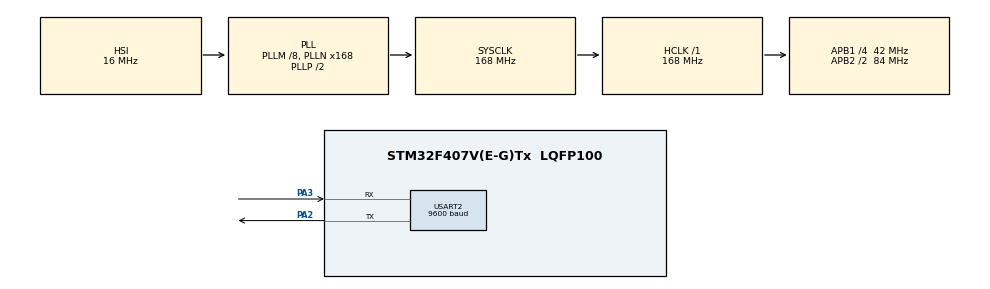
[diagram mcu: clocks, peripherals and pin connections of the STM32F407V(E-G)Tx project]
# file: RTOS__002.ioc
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FREERTOS.Tasks01=defaultTask,0,128,StartDefaultTask,Default,NULL,Dynamic,NULL,NULL
FREERTOS.configUSE_COUNTING_SEMAPHORES=1
Mcu.Family=STM32F4
Mcu.Name=STM32F407V(E-G)Tx
Mcu.Package=LQFP100
NVIC.PriorityGroup=NVIC_PRIORITYGROUP_4
NVIC.TIM1_UP_TIM10_IRQn=true\:15\:0\:false\:false\:true\:false\:false\:true\:true
NVIC.TimeBase=TIM1_UP_TIM10_IRQn
NVIC.TimeBaseIP=TIM1
NVIC.USART2_IRQn=true\:5\:0\:false\:false\:true\:true\:true\:true\:true
PA2.Mode=Asynchronous
PA2.Signal=USART2_TX
PA3.Mode=Asynchronous
PA3.Signal=USART2_RX
PH0-OSC_IN.Mode=HSE-External-Oscillator
PH0-OSC_IN.Signal=RCC_OSC_IN
PH1-OSC_OUT.Mode=HSE-External-Oscillator
PH1-OSC_OUT.Signal=RCC_OSC_OUT
ProjectManager.HeapSize=0x200
ProjectManager.StackSize=0x400
ProjectManager.TargetToolchain=STM32CubeIDE
RCC.48MHZClocksFreq_Value=84000000
RCC.AHBFreq_Value=168000000
RCC.APB1CLKDivider=RCC_HCLK_DIV4
RCC.APB1Freq_Value=42000000
RCC.APB1TimFreq_Value=84000000
RCC.APB2CLKDivider=RCC_HCLK_DIV2
RCC.APB2Freq_Value=84000000
RCC.APB2TimFreq_Value=168000000
RCC.CortexFreq_Value=168000000
RCC.HCLKFreq_Value=168000000
RCC.HSE_VALUE=8000000
RCC.HSI_VALUE=16000000
RCC.LSE_VALUE=32768
RCC.PLLM=8
RCC.PLLN=168
RCC.SYSCLKFreq_VALUE=168000000
RCC.SYSCLKSource=RCC_SYSCLKSOURCE_PLLCLK
RCC.VCOOutputFreq_Value=336000000
USART2.BaudRate=9600
USART2.VirtualMode=VM_ASYNC
VP_FREERTOS_VS_CMSIS_V1.Mode=CMSIS_V1
VP_SYS_VS_tim1.Mode=TIM1
board=custom

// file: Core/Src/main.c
/* USER CODE BEGIN Header */
/**
  ******************************************************************************
  * @file           : main.c
  * @brief          : Main program body
  ******************************************************************************
  * @attention
  *
  * Copyright (c) 2023 STMicroelectronics.
  * All rights reserved.
  *
  * This software is licensed under terms that can be found in the LICENSE file
  * in the root directory of this software component.
  * If no LICENSE file comes with this software, it is provided AS-IS.
  *
  ******************************************************************************
  */
/* USER CODE END Header */
#include "main.h"
// #include "cmsis_os.h"

/* USER CODE BEGIN Includes */

#include "FreeRTOS.h"
#include "task.h"
#include "timers.h"
#include "queue.h"
#include "semphr.h"
#include "event_groups.h"

#include "string.h"
#include "stdlib.h"

/* USER CODE END Includes */

UART_HandleTypeDef huart2;

osThreadId defaultTaskHandle;

void SystemClock_Config(void);
static void MX_GPIO_Init(void);
static void MX_USART2_UART_Init(void);

/* USER CODE BEGIN 0 */

// Create Task Defines

TaskHandle_t HPThandler;
void HPT_TASK(void *pvParameters);

TaskHandle_t MPThandler;
void MPT_TASK(void *pvParameters);

TaskHandle_t LPThandler;
void LPT_TASK(void *pvParameters);

TaskHandle_t VLPThandler;
void VLPT_TASK(void *pvParameters);

SemaphoreHandle_t CountingSem;

int resource[3] = {111,222,333};
int idx = 0;

uint8_t rx_data = 0;

/* USER CODE END 0 */

int main(void)
{

  /* MCU Configuration--------------------------------------------------------*/

  /* Reset of all peripherals, Initializes the Flash interface and the Systick. */
  HAL_Init();

  /* Configure the system clock */
  SystemClock_Config();

  /* Initialize all configured peripherals */
  MX_GPIO_Init();
  MX_USART2_UART_Init();
  /* USER CODE BEGIN 2 */

  CountingSem = xSemaphoreCreateCounting(3,0);

  if(CountingSem == NULL)
  {
	  HAL_UART_Transmit(&huart2, (uint8_t *)"Unable to Create Semaphore\n\n",28, 100);
  }
  else
  {
	  HAL_UART_Transmit(&huart2, (uint8_t *)"Counting Semaphorec created successfully\n\n",41, 100);
  }

  xTaskCreate(HPT_TASK, "HPT",128, NULL, 3, &HPThandler);
  xTaskCreate(MPT_TASK, "MPT",128, NULL, 2, &MPThandler);
  xTaskCreate(LPT_TASK, "LPT",128, NULL, 1, &LPThandler);
  xTaskCreate(VLPT_TASK, "VLPT",128, NULL, 0, &VLPThandler);

  vTaskStartScheduler();

  /* USER CODE END 2 */

  /* Create the thread(s) */
  /* definition and creation of defaultTask */

  /* We should never get here as control is now taken by the scheduler */
  /* Infinite loop */
  while (1)
  {

  }
}

void SystemClock_Config(void)
{
  RCC_OscInitTypeDef RCC_OscInitStruct = {0};
  RCC_ClkInitTypeDef RCC_ClkInitStruct = {0};

  /** Configure the main internal regulator output voltage
  */
  __HAL_RCC_PWR_CLK_ENABLE();
  __HAL_PWR_VOLTAGESCALING_CONFIG(PWR_REGULATOR_VOLTAGE_SCALE1);

  /** Initializes the RCC Oscillators according to the specified parameters
  * in the RCC_OscInitTypeDef structure.
  */
  RCC_OscInitStruct.OscillatorType = RCC_OSCILLATORTYPE_HSI;
  RCC_OscInitStruct.HSIState = RCC_HSI_ON;
  RCC_OscInitStruct.HSICalibrationValue = RCC_HSICALIBRATION_DEFAULT;
  RCC_OscInitStruct.PLL.PLLState = RCC_PLL_ON;
  RCC_OscInitStruct.PLL.PLLSource = RCC_PLLSOURCE_HSI;
  RCC_OscInitStruct.PLL.PLLM = 8;
  RCC_OscInitStruct.PLL.PLLN = 168;
  RCC_OscInitStruct.PLL.PLLP = RCC_PLLP_DIV2;
  RCC_OscInitStruct.PLL.PLLQ = 4;
  if (HAL_RCC_OscConfig(&RCC_OscInitStruct) != HAL_OK)
  {
    Error_Handler();
  }

  /** Initializes the CPU, AHB and APB buses clocks
  */
  RCC_ClkInitStruct.ClockType = RCC_CLOCKTYPE_HCLK|RCC_CLOCKTYPE_SYSCLK
                              |RCC_CLOCKTYPE_PCLK1|RCC_CLOCKTYPE_PCLK2;
  RCC_ClkInitStruct.SYSCLKSource = RCC_SYSCLKSOURCE_PLLCLK;
  RCC_ClkInitStruct.AHBCLKDivider = RCC_SYSCLK_DIV1;
  RCC_ClkInitStruct.APB1CLKDivider = RCC_HCLK_DIV4;
  RCC_ClkInitStruct.APB2CLKDivider = RCC_HCLK_DIV2;

  if (HAL_RCC_ClockConfig(&RCC_ClkInitStruct, FLASH_LATENCY_5) != HAL_OK)
  {
    Error_Handler();
  }
}

static void MX_USART2_UART_Init(void)
{

  huart2.Instance = USART2;
  huart2.Init.BaudRate = 9600;
  huart2.Init.WordLength = UART_WORDLENGTH_8B;
  huart2.Init.StopBits = UART_STOPBITS_1;
  huart2.Init.Parity = UART_PARITY_NONE;
  huart2.Init.Mode = UART_MODE_TX_RX;
  huart2.Init.HwFlowCtl = UART_HWCONTROL_NONE;
  huart2.Init.OverSampling = UART_OVERSAMPLING_16;
  if (HAL_UART_Init(&huart2) != HAL_OK)
  {
    Error_Handler();
  }

}

static void MX_GPIO_Init(void)
{

  /* GPIO Ports Clock Enable */
  __HAL_RCC_GPIOH_CLK_ENABLE();
  __HAL_RCC_GPIOA_CLK_ENABLE();

}

void HAL_TIM_PeriodElapsedCallback(TIM_HandleTypeDef *htim)
{
  if (htim->Instance == TIM1) {
    HAL_IncTick();
  }
}

void Error_Handler(void)
{
  __disable_irq();
  while (1)
  {
  }
}
